# XMC4300 register map
Vendor: Infineon; File version: 0.5.1 (Superset device XMC4800)
CPU: CM4 r2p0, little endian, MPU, FPU, 6 interrupt priority bits
Registers are 32-bit, read-write, reset 0x0 unless marked. A register's access mark holds for its fields unless they carry their own. Offsets are from the block's base; [hi:lo] are bit positions.

## SCU_CLK — System Control Unit
Base 0x50004600
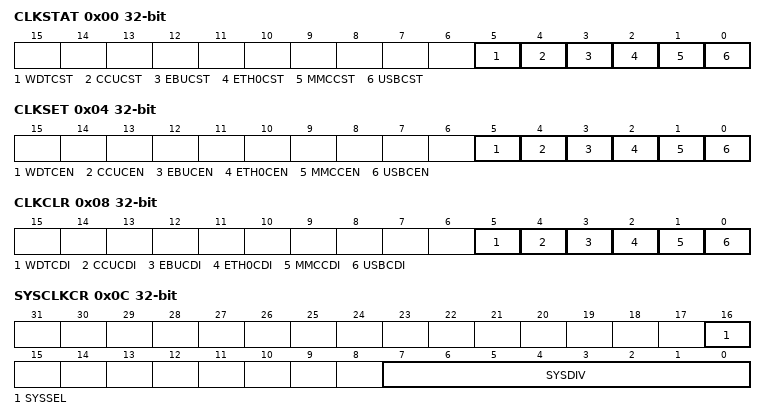
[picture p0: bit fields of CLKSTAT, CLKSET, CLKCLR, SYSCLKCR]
0x00 CLKSTAT ro — Clock Status Register
  [all] fields
    0=Clock disabled; 1=Clock enabled
  [5] WDTCST — WDT Clock Status
  [4] CCUCST — CCU Clock Status
  [3] EBUCST — EBU Clock Status
  [2] ETH0CST — Ethernet Clock Status
  [1] MMCCST — MMC Clock Status
  [0] USBCST — USB Clock Status
0x04 CLKSET wo
  [all] fields
    0=No effect; 1=Enable
  [5] WDTCEN — WDT Clock Enable
  [4] CCUCEN — CCU Clock Enable
  [3] EBUCEN — EBU Clock Enable
  [2] ETH0CEN — Ethernet Clock Enable
  [1] MMCCEN — MMC Clock Enable
  [0] USBCEN — USB Clock Enable
0x08 CLKCLR wo — CLK Clear Register
  [all] fields
    0=No effect; 1=Disable clock
  [5] WDTCDI — WDT Clock Disable
  [4] CCUCDI — CCU Clock Disable
  [3] EBUCDI — EBU Clock Disable
  [2] ETH0CDI — Ethernet Clock Disable
  [1] MMCCDI — MMC Clock Disable
  [0] USBCDI — USB Clock Disable
0x0C SYSCLKCR — System Clock Control Register
  [16] SYSSEL — System Clock Selection Value
    0=fOFI clock; 1=fPLL clock
  [7:0] SYSDIV — System Clock Division Value
0x10 CPUCLKCR — CPU Clock Control Register
  [0] CPUDIV — CPU Clock Divider Enable
    0=fCPU = fSYS; 1=fCPU = fSYS / 2
0x14 PBCLKCR — Peripheral Bus Clock Control Register
  [0] PBDIV — PB Clock Divider Enable
    0=fPERIPH = fCPU; 1=fPERIPH = fCPU / 2
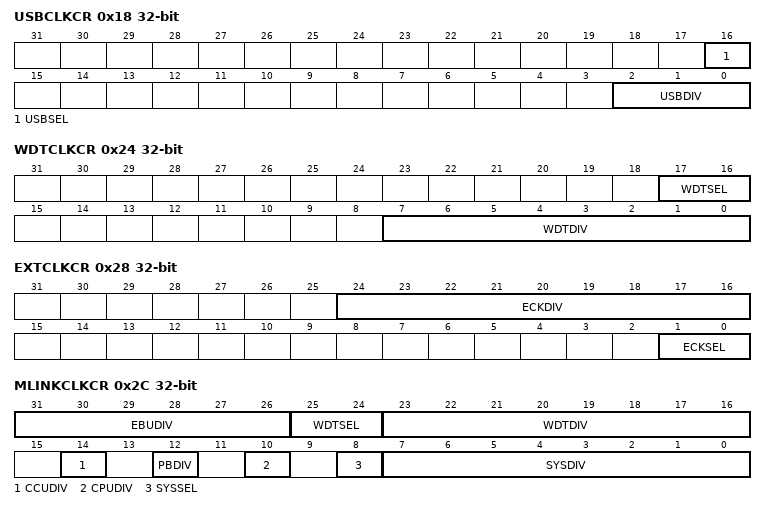
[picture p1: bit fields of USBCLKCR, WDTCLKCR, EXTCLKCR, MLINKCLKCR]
0x18 USBCLKCR — USB Clock Control Register
  [16] USBSEL — USB Clock Selection Value
    0=USB PLL Clock; 1=PLL Clock
  [2:0] USBDIV — USB Clock Divider Value
0x1C EBUCLKCR — EBU Clock Control Register
  [5:0] EBUDIV — EBU Clock Divider Value
0x20 CCUCLKCR — CCU Clock Control Register
  [0] CCUDIV — CCU Clock Divider Enable
    0=fCCU = fSYS; 1=fCCU = fSYS / 2
0x24 WDTCLKCR — WDT Clock Control Register
  [17:16] WDTSEL — WDT Clock Selection Value
    0=fOFI clock; 1=fSTDBY clock; 2=fPLL clock
  [7:0] WDTDIV — WDT Clock Divider Value
0x28 EXTCLKCR — External Clock Control
  [24:16] ECKDIV — External Clock Divider Value
  [1:0] ECKSEL — External Clock Selection Value
    0=fSYS clock; 2=fUSB clock; 3=fPLL clock divided according to ECKDIV bit field configuration
0x2C MLINKCLKCR — Multi-Link Clock Control
  [31:26] EBUDIV — EBU Clock Divider Value
  [25:24] WDTSEL — WDT Clock Selection Value
    0=fOFIclock; 1=fSTDBYclock; 2=fPLLclock
  [23:16] WDTDIV — WDT Clock Divider Value
  [14] CCUDIV — CCU Clock Divider Enable
    0=fCCU=fSYS; 1=fCCU=fSYS/ 2
  [12] PBDIV — PB Clock Divider Enable
    0=fPERIPH=fCPU; 1=fPERIPH=fCPU/ 2
  [10] CPUDIV — CPU Clock Divider Enable
    0=fCPU=fSYS; 1=fCPU=fSYS/ 2
  [8] SYSSEL — System Clock Selection Value
    0=fOFIclock; 1=fPLLclock
  [7:0] SYSDIV — System Clock Division Value
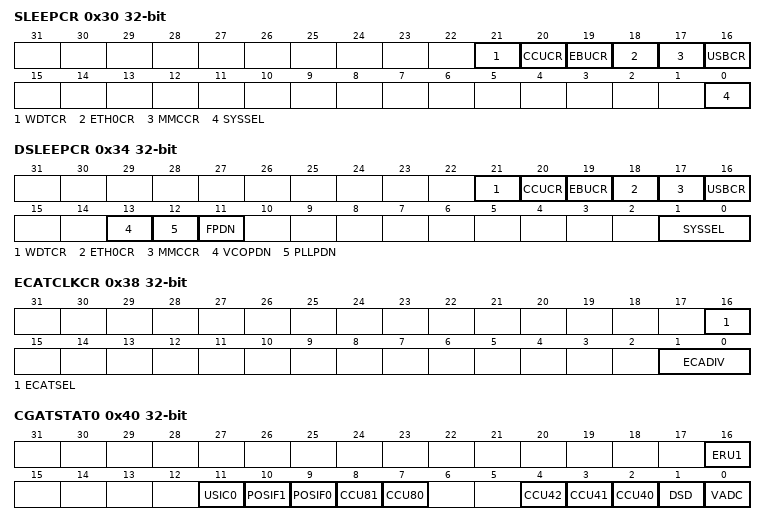
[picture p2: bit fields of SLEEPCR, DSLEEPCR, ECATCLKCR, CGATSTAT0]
0x30 SLEEPCR — Sleep Control Register
  [21] WDTCR — WDT Clock Control
    0=Disable; 1=Enable
  [20] CCUCR — CCU Clock Control
    0=Disable; 1=Enable
  [19] EBUCR — EBU Clock Control
    0=Disable; 1=Enable
  [18] ETH0CR — Ethernet Clock Control
    0=Disable; 1=Enable
  [17] MMCCR — MMC Clock Control
    0=Disable; 1=Enable
  [16] USBCR — USB Clock Control
    0=Disable; 1=Enable
  [0] SYSSEL — System Clock Selection Value
    0=fOFI clock; 1=fPLL clock
0x34 DSLEEPCR — Deep Sleep Control Register
  [21] WDTCR — WDT Clock Control
    0=Disable; 1=Enable
  [20] CCUCR — CCU Clock Control
    0=Disable; 1=Enable
  [19] EBUCR — EBU Clock Control
    0=Disable; 1=Enable
  [18] ETH0CR — Ethernet Clock Control
    0=Disable; 1=Enable
  [17] MMCCR — MMC Clock Control
    0=Disable; 1=Enable
  [16] USBCR — USB Clock Control
    0=Disable; 1=Enable
  [13] VCOPDN — VCO Power Down
    1=Switch off VCO of main PLL; 0=No effect
  [12] PLLPDN — PLL Power Down
    1=Switch off main PLL; 0=No effect
  [11] FPDN — Flash Power Down
    1=Flash power down module; 0=No effect
  [1:0] SYSSEL — System Clock Selection Value
    0=fOFI clock; 1=fPLL clock
0x38 ECATCLKCR — EtherCAT Clock Control Register
  [16] ECATSEL — EtherCAT Clock Selection Value
    0=fPLLUSBclock; 1=fPLLclock
  [1:0] ECADIV — EtherCAT Clock Divider Value
0x40 CGATSTAT0 ro — Peripheral 0 Clock Gating Status
  [all] fields
    0=Gating de-asserted; 1=Gating asserted
  [16] ERU1 — ERU1 Gating Status
  [11] USIC0 — USIC0 Gating Status
  [10] POSIF1 — POSIF1 Gating Status
  [9] POSIF0 — POSIF0 Gating Status
  [8] CCU81 — CCU81 Gating Status
  [7] CCU80 — CCU80 Gating Status
  [4] CCU42 — CCU42 Gating Status
  [3] CCU41 — CCU41 Gating Status
  [2] CCU40 — CCU40 Gating Status
  [1] DSD — DSD Gating Status
  [0] VADC — VADC Gating Status
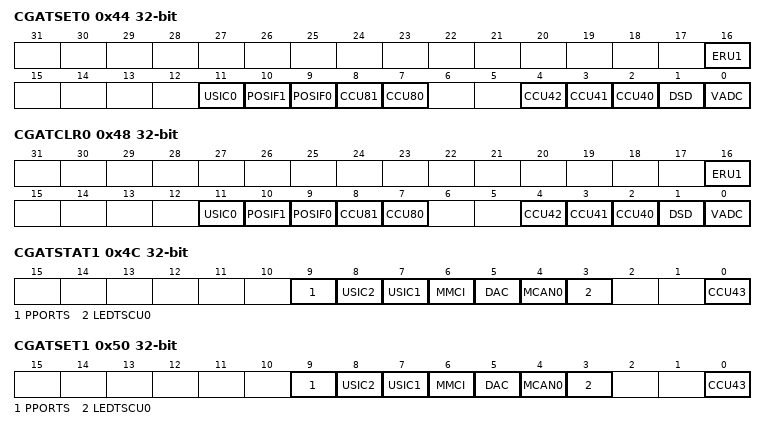
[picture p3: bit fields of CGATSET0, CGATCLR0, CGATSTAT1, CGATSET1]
0x44 CGATSET0 wo — Peripheral 0 Clock Gating Set
  [all] fields
    0=No effect; 1=Enable gating
  [16] ERU1 — ERU1 Gating Set
  [11] USIC0 — USIC0 Gating Set
  [10] POSIF1 — POSIF1 Gating Set
  [9] POSIF0 — POSIF0 Gating Set
  [8] CCU81 — CCU81 Gating Set
  [7] CCU80 — CCU80 Gating Set
  [4] CCU42 — CCU42 Gating Set
  [3] CCU41 — CCU41 Gating Set
  [2] CCU40 — CCU40 Gating Set
  [1] DSD — DSD Gating Set
  [0] VADC — VADC Gating Set
0x48 CGATCLR0 wo — Peripheral 0 Clock Gating Clear
  [all] fields
    0=No effect; 1=Disable gating
  [16] ERU1 — ERU1 Gating Clear
  [11] USIC0 — USIC0 Gating Clear
  [10] POSIF1 — POSIF1 Gating Clear
  [9] POSIF0 — POSIF0 Gating Clear
  [8] CCU81 — CCU81 Gating Clear
  [7] CCU80 — CCU80 Gating Clear
  [4] CCU42 — CCU42 Gating Clear
  [3] CCU41 — CCU41 Gating Clear
  [2] CCU40 — CCU40 Gating Clear
  [1] DSD — DSD Gating Clear
  [0] VADC — VADC Gating Clear
0x4C CGATSTAT1 ro — Peripheral 1 Clock Gating Status
  [all] fields
    0=Gating de-asserted; 1=Gating asserted
  [9] PPORTS — PORTS Gating Status
  [8] USIC2 — USIC2 Gating Status
  [7] USIC1 — USIC1 Gating Status
  [6] MMCI — MMC Interface Gating Status
  [5] DAC — DAC Gating Status
  [4] MCAN0 — MultiCAN Gating Status
  [3] LEDTSCU0 — LEDTS Gating Status
  [0] CCU43 — CCU43 Gating Status
0x50 CGATSET1 wo — Peripheral 1 Clock Gating Set
  [all] fields
    0=No effect; 1=Enable gating
  [9] PPORTS — PORTS Gating Set
  [8] USIC2 — USIC2 Gating Set
  [7] USIC1 — USIC1 Gating Set
  [6] MMCI — MMC Interface Gating Set
  [5] DAC — DAC Gating Set
  [4] MCAN0 — MultiCAN Gating Set
  [3] LEDTSCU0 — LEDTS Gating Set
  [0] CCU43 — CCU43 Gating Set
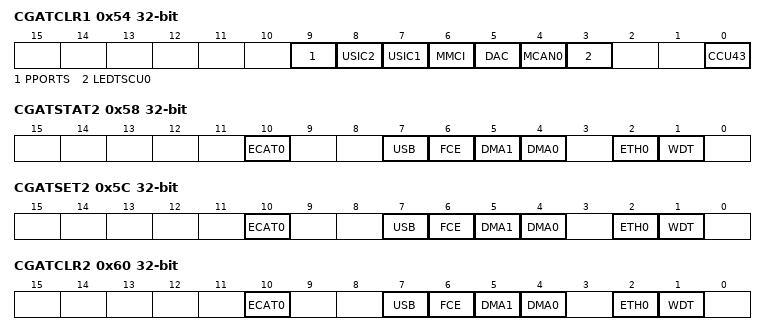
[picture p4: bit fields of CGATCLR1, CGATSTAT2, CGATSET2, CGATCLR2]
0x54 CGATCLR1 wo — Peripheral 1 Clock Gating Clear
  [all] fields
    0=No effect; 1=Disable gating
  [9] PPORTS — PORTS Gating Clear
  [8] USIC2 — USIC2 Gating Clear
  [7] USIC1 — USIC1 Gating Clear
  [6] MMCI — MMC Interface Gating Clear
  [5] DAC — DAC Gating Clear
  [4] MCAN0 — MultiCAN Gating Clear
  [3] LEDTSCU0 — LEDTS Gating Clear
  [0] CCU43 — CCU43 Gating Clear
0x58 CGATSTAT2 ro — Peripheral 2 Clock Gating Status
  [all] fields
    0=Gating de-asserted; 1=Gating asserted
  [10] ECAT0 — ECAT0 Gating Status
  [7] USB — USB Gating Status
  [6] FCE — FCE Gating Status
  [5] DMA1 — DMA1 Gating Status
  [4] DMA0 — DMA0 Gating Status
  [2] ETH0 — ETH0 Gating Status
  [1] WDT — WDT Gating Status
0x5C CGATSET2 wo — Peripheral 2 Clock Gating Set
  [all] fields
    0=No effect; 1=Enable gating
  [10] ECAT0 — ECAT0 Gating Set
  [7] USB — USB Gating Set
  [6] FCE — FCE Gating Set
  [5] DMA1 — DMA1 Gating Set
  [4] DMA0 — DMA0 Gating Set
  [2] ETH0 — ETH0 Gating Set
  [1] WDT — WDT Gating Set
0x60 CGATCLR2 wo — Peripheral 2 Clock Gating Clear
  [all] fields
    0=No effect; 1=Disable gating
  [10] ECAT0 — ECAT0 Gating Clear
  [7] USB — USB Gating Clear
  [6] FCE — FCE Gating Clear
  [5] DMA1 — DMA1 Gating Clear
  [4] DMA0 — DMA0 Gating Clear
  [2] ETH0 — ETH0 Gating Clear
  [1] WDT — WDT Gating Clear
0x64 CGATSTAT3 ro — Peripheral 3 Clock Gating Status
  [2] EBU — EBU Gating Status
    0=Gating de-asserted; 1=Gating asserted
0x68 CGATSET3 wo — Peripheral 3 Clock Gating Set
  [2] EBU — EBU Gating Set
    0=No effect; 1=Enable gating
0x6C CGATCLR3 wo — Peripheral 3 Clock Gating Clear
  [2] EBU — EBU Gating Clear
    0=No effect; 1=Disable gating
